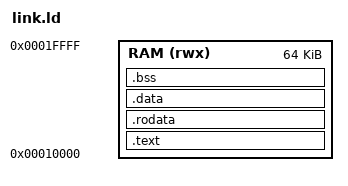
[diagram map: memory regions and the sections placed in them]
/* link.ld — whole program in main RAM (64 KiB at 0x0001_0000). */
OUTPUT_ARCH(riscv)
ENTRY(_start)
MEMORY { RAM (rwx) : ORIGIN = 0x00010000, LENGTH = 64K }
SECTIONS
{
    .text : { KEEP(*(.text.start)) *(.text .text.*) } > RAM
    .rodata : { *(.rodata .rodata.* .srodata .srodata.*) } > RAM
    .data : { *(.data .data.* .sdata .sdata.*) } > RAM
    .bss (NOLOAD) : ALIGN(4) {
        __bss_start = .;
        *(.bss .bss.* .sbss .sbss.* COMMON)
        . = ALIGN(4);
        __bss_end = .;
    } > RAM
    _stack_top = ORIGIN(RAM) + LENGTH(RAM);
    /DISCARD/ : { *(.comment) *(.riscv.attributes) *(.note*) *(.eh_frame*) }
}
